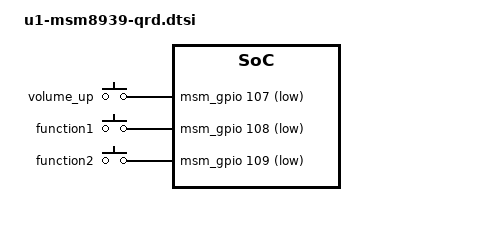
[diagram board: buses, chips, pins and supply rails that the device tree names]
/* Copyright (c) 2014, The Linux Foundation. All rights reserved.
 *
 * This program is free software; you can redistribute it and/or modify
 * it under the terms of the GNU General Public License version 2 and
 * only version 2 as published by the Free Software Foundation.
 *
 * This program is distributed in the hope that it will be useful,
 * but WITHOUT ANY WARRANTY; without even the implied warranty of
 * MERCHANTABILITY or FITNESS FOR A PARTICULAR PURPOSE.  See the
 * GNU General Public License for more details.
 */

&sdhc_2 {
	status = "disabled";
};

&apc_vreg_corner {
	vdd-apc-supply = <&fan53555>;
	vdd-apcncp-supply = <&ncp6335d>;
};

&soc {
	gpio_keys {
		compatible = "gpio-keys";
		input-name = "gpio-keys";
		pinctrl-names = "tlmm_gpio_key_active","tlmm_gpio_key_suspend";
		pinctrl-0 = <&gpio_key_active>;
		pinctrl-1 = <&gpio_key_suspend>;

		vol_up {
			label = "volume_up";
			gpios = <&msm_gpio 107 0x1>;
			linux,input-type = <1>;
			linux,code = <115>;
			gpio-key,wakeup;
			debounce-interval = <15>;
		};

		function1 {
			label = "function1";
			gpios = <&msm_gpio 108 0x1>;
			linux,input-type = <1>;
			linux,code = <224>;
			gpio-key,wakeup;
			debounce-interval = <15>;
		};

		function2 {
			label = "function2";
			gpios = <&msm_gpio 109 0x1>;
			linux,input-type = <1>;
			linux,code = <225>;
			gpio-key,wakeup;
			debounce-interval = <15>;
		};
	};
};
